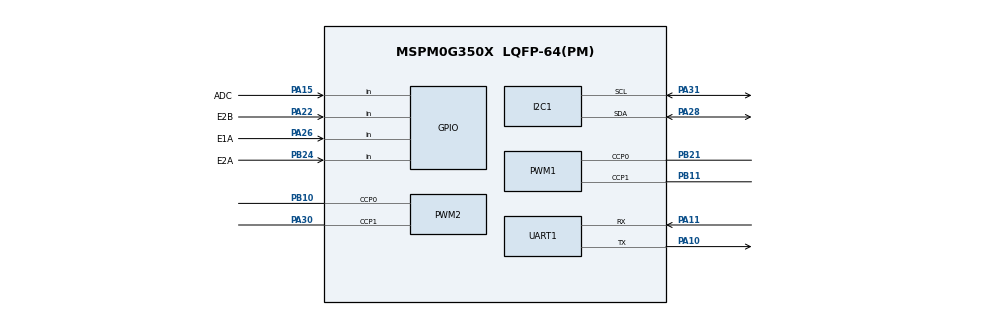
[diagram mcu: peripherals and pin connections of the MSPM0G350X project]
/**
 * @cliArgs --device "MSPM0G350X" --part "Default" --package "LQFP-64(PM)" --product "mspm0_sdk@2.10.00.04"
 * @versions {"tool":"1.26.2+4477"}
 */

/**
 * Import the modules used in this configuration.
 */
const GPIO    = scripting.addModule("/ti/driverlib/GPIO", {}, false);
const GPIO1   = GPIO.addInstance();
const GPIO2   = GPIO.addInstance();
const I2C     = scripting.addModule("/ti/driverlib/I2C", {}, false);
const I2C1    = I2C.addInstance();
const PWM     = scripting.addModule("/ti/driverlib/PWM", {}, false);
const PWM1    = PWM.addInstance();
const PWM2    = PWM.addInstance();
const SYSCTL  = scripting.addModule("/ti/driverlib/SYSCTL");
const SYSTICK = scripting.addModule("/ti/driverlib/SYSTICK");
const TIMER   = scripting.addModule("/ti/driverlib/TIMER", {}, false);
const TIMER1  = TIMER.addInstance();
const UART    = scripting.addModule("/ti/driverlib/UART", {}, false);
const UART1   = UART.addInstance();

/**
 * Write custom configuration values to the imported modules.
 */
const gate7  = system.clockTree["MFCLKGATE"];
gate7.enable = true;

GPIO1.$name                          = "MotorMonitor";
GPIO1.associatedPins.create(5);
GPIO1.associatedPins[0].$name        = "E1A";
GPIO1.associatedPins[0].direction    = "INPUT";
GPIO1.associatedPins[0].assignedPort = "PORTA";
GPIO1.associatedPins[0].assignedPin  = "26";
GPIO1.associatedPins[0].pin.$assign  = "PA26";
GPIO1.associatedPins[1].$name        = "E1B";
GPIO1.associatedPins[1].direction    = "INPUT";
GPIO1.associatedPins[1].assignedPort = "PORTA";
GPIO1.associatedPins[1].assignedPin  = "24";
GPIO1.associatedPins[2].$name        = "E2A";
GPIO1.associatedPins[2].direction    = "INPUT";
GPIO1.associatedPins[2].assignedPort = "PORTB";
GPIO1.associatedPins[2].assignedPin  = "24";
GPIO1.associatedPins[2].pin.$assign  = "PB24";
GPIO1.associatedPins[3].$name        = "E2B";
GPIO1.associatedPins[3].direction    = "INPUT";
GPIO1.associatedPins[3].assignedPort = "PORTA";
GPIO1.associatedPins[3].assignedPin  = "22";
GPIO1.associatedPins[3].pin.$assign  = "PA22";
GPIO1.associatedPins[4].$name        = "ADC";
GPIO1.associatedPins[4].direction    = "INPUT";
GPIO1.associatedPins[4].assignedPort = "PORTA";
GPIO1.associatedPins[4].assignedPin  = "15";
GPIO1.associatedPins[4].pin.$assign  = "PA15";

const Board = scripting.addModule("/ti/driverlib/Board", {}, false);

GPIO2.$name                          = "GrayS";
GPIO2.associatedPins.create(4);
GPIO2.associatedPins[0].assignedPort = "PORTA";
GPIO2.associatedPins[0].assignedPin  = "25";
GPIO2.associatedPins[0].$name        = "AD0";
GPIO2.associatedPins[1].$name        = "AD1";
GPIO2.associatedPins[1].assignedPort = "PORTB";
GPIO2.associatedPins[1].assignedPin  = "25";
GPIO2.associatedPins[2].$name        = "AD2";
GPIO2.associatedPins[2].assignedPort = "PORTB";
GPIO2.associatedPins[2].assignedPin  = "20";
GPIO2.associatedPins[3].$name        = "OUT";
GPIO2.associatedPins[3].direction    = "INPUT";
GPIO2.associatedPins[3].assignedPort = "PORTA";
GPIO2.associatedPins[3].assignedPin  = "14";

I2C1.$name                           = "I2C_0";
I2C1.basicEnableTarget               = true;
I2C1.advDigitalGlitchFilter          = "CLOCKS_1";
I2C1.enableDMAEvent1                 = false;
I2C1.enableDMAEvent2                 = false;
I2C1.basicEnableController           = true;
I2C1.basicControllerStandardBusSpeed = "Fast";
I2C1.basicTargetSecAddressEnable     = true;
I2C1.peripheral.sdaPin.$assign       = "PA28";
I2C1.peripheral.sclPin.$assign       = "PA31";
I2C1.sdaPinConfig.$name              = "ti_driverlib_gpio_GPIOPinGeneric4";
I2C1.sclPinConfig.$name              = "ti_driverlib_gpio_GPIOPinGeneric5";

PWM1.timerCount                         = 3200;
PWM1.$name                              = "MotorLeft";
PWM1.peripheral.$assign                 = "TIMG8";
PWM1.peripheral.ccp0Pin.$assign         = "PB21";
PWM1.peripheral.ccp1Pin.$assign         = "PB11";
PWM1.PWM_CHANNEL_0.$name                = "ti_driverlib_pwm_PWMTimerCC0";
PWM1.PWM_CHANNEL_1.$name                = "ti_driverlib_pwm_PWMTimerCC1";
PWM1.ccp0PinConfig.$name                = "ti_driverlib_gpio_GPIOPinGeneric2";
PWM1.ccp0PinConfig.direction            = scripting.forceWrite("OUTPUT");
PWM1.ccp0PinConfig.hideOutputInversion  = scripting.forceWrite(false);
PWM1.ccp0PinConfig.onlyInternalResistor = scripting.forceWrite(false);
PWM1.ccp0PinConfig.passedPeripheralType = scripting.forceWrite("Digital");
PWM1.ccp0PinConfig.enableConfig         = true;
PWM1.ccp1PinConfig.$name                = "ti_driverlib_gpio_GPIOPinGeneric3";
PWM1.ccp1PinConfig.direction            = scripting.forceWrite("OUTPUT");
PWM1.ccp1PinConfig.hideOutputInversion  = scripting.forceWrite(false);
PWM1.ccp1PinConfig.onlyInternalResistor = scripting.forceWrite(false);
PWM1.ccp1PinConfig.passedPeripheralType = scripting.forceWrite("Digital");
PWM1.ccp1PinConfig.enableConfig         = true;

PWM2.$name                              = "MotorRight";
PWM2.peripheral.$assign                 = "TIMG6";
PWM2.peripheral.ccp0Pin.$assign         = "PB10";
PWM2.peripheral.ccp1Pin.$assign         = "PA30";
PWM2.PWM_CHANNEL_0.$name                = "ti_driverlib_pwm_PWMTimerCC2";
PWM2.PWM_CHANNEL_1.$name                = "ti_driverlib_pwm_PWMTimerCC3";
PWM2.ccp0PinConfig.$name                = "ti_driverlib_gpio_GPIOPinGeneric6";
PWM2.ccp0PinConfig.direction            = scripting.forceWrite("OUTPUT");
PWM2.ccp0PinConfig.hideOutputInversion  = scripting.forceWrite(false);
PWM2.ccp0PinConfig.onlyInternalResistor = scripting.forceWrite(false);
PWM2.ccp0PinConfig.passedPeripheralType = scripting.forceWrite("Digital");
PWM2.ccp0PinConfig.enableConfig         = true;
PWM2.ccp1PinConfig.$name                = "ti_driverlib_gpio_GPIOPinGeneric7";
PWM2.ccp1PinConfig.direction            = scripting.forceWrite("OUTPUT");
PWM2.ccp1PinConfig.hideOutputInversion  = scripting.forceWrite(false);
PWM2.ccp1PinConfig.onlyInternalResistor = scripting.forceWrite(false);
PWM2.ccp1PinConfig.passedPeripheralType = scripting.forceWrite("Digital");
PWM2.ccp1PinConfig.enableConfig         = true;

SYSCTL.forceDefaultClkConfig = true;
SYSCTL.clockTreeEn           = true;

SYSTICK.periodEnable  = true;
SYSTICK.systickEnable = true;
SYSTICK.period        = 16777216;

TIMER1.$name = "TIM_0";

UART1.$name                    = "UART_0";
UART1.enabledInterrupts        = ["RX"];
UART1.uartClkSrc               = "MFCLK";
UART1.peripheral.rxPin.$assign = "PA11";
UART1.peripheral.txPin.$assign = "PA10";
UART1.txPinConfig.$name        = "ti_driverlib_gpio_GPIOPinGeneric0";
UART1.rxPinConfig.$name        = "ti_driverlib_gpio_GPIOPinGeneric1";

/**
 * Pinmux solution for unlocked pins/peripherals. This ensures that minor changes to the automatic solver in a future
 * version of the tool will not impact the pinmux you originally saw.  These lines can be completely deleted in order to
 * re-solve from scratch.
 */
GPIO1.associatedPins[1].pin.$suggestSolution = "PA24";
Board.peripheral.$suggestSolution            = "DEBUGSS";
Board.peripheral.swclkPin.$suggestSolution   = "PA20";
Board.peripheral.swdioPin.$suggestSolution   = "PA19";
GPIO2.associatedPins[0].pin.$suggestSolution = "PA25";
GPIO2.associatedPins[1].pin.$suggestSolution = "PB25";
GPIO2.associatedPins[2].pin.$suggestSolution = "PB20";
GPIO2.associatedPins[3].pin.$suggestSolution = "PA14";
I2C1.peripheral.$suggestSolution             = "I2C0";
TIMER1.peripheral.$suggestSolution           = "TIMA0";
UART1.peripheral.$suggestSolution            = "UART0";
